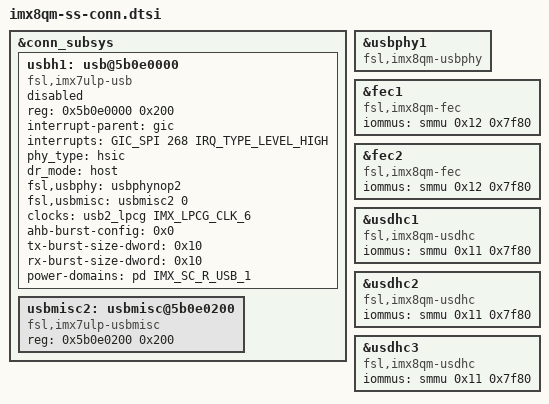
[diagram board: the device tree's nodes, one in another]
// SPDX-License-Identifier: GPL-2.0+
/*
 * Copyright 2019-2020 NXP
 *	Dong Aisheng <aisheng.dong@nxp.com>
 */

&conn_subsys {
	usbh1: usb@5b0e0000 {
		compatible = "fsl,imx7ulp-usb", "fsl,imx6ul-usb", "fsl,imx27-usb";
		reg = <0x5b0e0000 0x200>;
		interrupt-parent = <&gic>;
		interrupts = <GIC_SPI 268 IRQ_TYPE_LEVEL_HIGH>;
		phy_type = "hsic";
		dr_mode = "host";
		fsl,usbphy = <&usbphynop2>;
		fsl,usbmisc = <&usbmisc2 0>;
		clocks = <&usb2_lpcg IMX_LPCG_CLK_6>;
		ahb-burst-config = <0x0>;
		tx-burst-size-dword = <0x10>;
		rx-burst-size-dword = <0x10>;
		#stream-id-cells = <1>;
		power-domains = <&pd IMX_SC_R_USB_1>;
		status = "disabled";
	};

	usbmisc2: usbmisc@5b0e0200 {
		compatible = "fsl,imx7ulp-usbmisc", "fsl,imx7d-usbmisc", "fsl,imx6q-usbmisc";
		#index-cells = <1>;
		reg = <0x5b0e0200 0x200>;
	};
};

&usbphy1 {
	compatible = "fsl,imx8qm-usbphy", "fsl,imx7ulp-usbphy";
};

&fec1 {
	compatible = "fsl,imx8qm-fec", "fsl,imx6sx-fec";
	iommus = <&smmu 0x12 0x7f80>;
};

&fec2 {
	compatible = "fsl,imx8qm-fec", "fsl,imx6sx-fec";
	iommus = <&smmu 0x12 0x7f80>;
};

&usdhc1 {
	compatible = "fsl,imx8qm-usdhc", "fsl,imx8qxp-usdhc", "fsl,imx7d-usdhc";
	iommus = <&smmu 0x11 0x7f80>;
};

&usdhc2 {
	compatible = "fsl,imx8qm-usdhc", "fsl,imx8qxp-usdhc", "fsl,imx7d-usdhc";
	iommus = <&smmu 0x11 0x7f80>;
};

&usdhc3 {
	compatible = "fsl,imx8qm-usdhc", "fsl,imx8qxp-usdhc", "fsl,imx7d-usdhc";
	iommus = <&smmu 0x11 0x7f80>;
};
